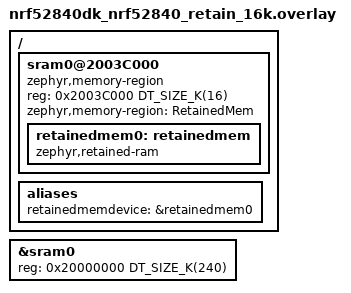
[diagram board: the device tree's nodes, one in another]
/ {
	sram0@2003C000 {
		compatible = "zephyr,memory-region", "mmio-sram";
		reg = <0x2003C000 DT_SIZE_K(16)>;
		zephyr,memory-region = "RetainedMem";
		status = "okay";

		retainedmem0: retainedmem {
			compatible = "zephyr,retained-ram";
			status = "okay";
		};
	};

	aliases {
		retainedmemdevice = &retainedmem0;
	};
};

&sram0 {
	/* Shrink SRAM size to avoid overlap with retained memory region */
	reg = <0x20000000 DT_SIZE_K(240)>;
};
